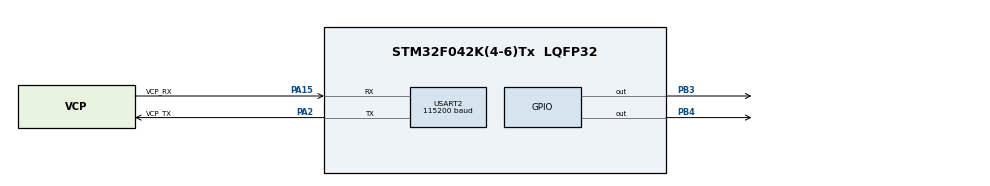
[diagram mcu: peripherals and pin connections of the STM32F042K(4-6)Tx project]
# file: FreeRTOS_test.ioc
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FREERTOS.Tasks01=defaultTask,0,128,StartDefaultTask,Default,NULL,Dynamic,NULL,NULL;Task2,0,128,Task2_init,Default,NULL,Dynamic,NULL,NULL
Mcu.Family=STM32F0
Mcu.Name=STM32F042K(4-6)Tx
Mcu.Package=LQFP32
NVIC.TIM17_IRQn=true\:3\:0\:false\:false\:true\:false\:false\:true
NVIC.TimeBase=TIM17_IRQn
NVIC.TimeBaseIP=TIM17
PA13.GPIO_Label=SWDIO
PA13.Mode=Serial_Wire
PA13.Signal=SYS_SWDIO
PA14.GPIO_Label=SWCLK
PA14.Mode=Serial_Wire
PA14.Signal=SYS_SWCLK
PA15.GPIO_Label=VCP_RX
PA15.Mode=Asynchronous
PA15.Signal=USART2_RX
PA2.GPIO_Label=VCP_TX
PA2.Mode=Asynchronous
PA2.Signal=USART2_TX
PB3.Signal=GPIO_Output
PB4.Signal=GPIO_Output
PF0-OSC_IN.GPIO_Label=MCO
PF0-OSC_IN.Mode=HSE-External-Clock-Source
PF0-OSC_IN.Signal=RCC_OSC_IN
ProjectManager.HeapSize=0x200
ProjectManager.StackSize=0x400
ProjectManager.TargetToolchain=MDK-ARM V5.32
USART2.BaudRate=115200
USART2.VirtualMode-Asynchronous=VM_ASYNC
VP_FREERTOS_VS_CMSIS_V1.Mode=CMSIS_V1
VP_SYS_VS_tim17.Mode=TIM17
board=NUCLEO-F042K6

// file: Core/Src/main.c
/* USER CODE BEGIN Header */
/**
  ******************************************************************************
  * @file           : main.c
  * @brief          : Main program body
  ******************************************************************************
  * @attention
  *
  * Copyright (c) 2022 STMicroelectronics.
  * All rights reserved.
  *
  * This software is licensed under terms that can be found in the LICENSE file
  * in the root directory of this software component.
  * If no LICENSE file comes with this software, it is provided AS-IS.
  *
  ******************************************************************************
  */
/* USER CODE END Header */
#include "main.h"
#include "cmsis_os.h"
#include "usart.h"
#include "gpio.h"

void SystemClock_Config(void);
void MX_FREERTOS_Init(void);

int main(void)
{

  /* MCU Configuration--------------------------------------------------------*/

  /* Reset of all peripherals, Initializes the Flash interface and the Systick. */
  HAL_Init();

  /* Configure the system clock */
  SystemClock_Config();

  /* Initialize all configured peripherals */
  MX_GPIO_Init();
  MX_USART2_UART_Init();

  /* Call init function for freertos objects (in freertos.c) */
  MX_FREERTOS_Init();
  /* Start scheduler */
  osKernelStart();

  /* We should never get here as control is now taken by the scheduler */
  /* Infinite loop */
  while (1)
  {

  }
}

void SystemClock_Config(void)
{
  RCC_OscInitTypeDef RCC_OscInitStruct = {0};
  RCC_ClkInitTypeDef RCC_ClkInitStruct = {0};

  /** Initializes the RCC Oscillators according to the specified parameters
  * in the RCC_OscInitTypeDef structure.
  */
  RCC_OscInitStruct.OscillatorType = RCC_OSCILLATORTYPE_HSI;
  RCC_OscInitStruct.HSIState = RCC_HSI_ON;
  RCC_OscInitStruct.HSICalibrationValue = RCC_HSICALIBRATION_DEFAULT;
  RCC_OscInitStruct.PLL.PLLState = RCC_PLL_NONE;
  if (HAL_RCC_OscConfig(&RCC_OscInitStruct) != HAL_OK)
  {
    Error_Handler();
  }
  /** Initializes the CPU, AHB and APB buses clocks
  */
  RCC_ClkInitStruct.ClockType = RCC_CLOCKTYPE_HCLK|RCC_CLOCKTYPE_SYSCLK
                              |RCC_CLOCKTYPE_PCLK1;
  RCC_ClkInitStruct.SYSCLKSource = RCC_SYSCLKSOURCE_HSI;
  RCC_ClkInitStruct.AHBCLKDivider = RCC_SYSCLK_DIV1;
  RCC_ClkInitStruct.APB1CLKDivider = RCC_HCLK_DIV1;

  if (HAL_RCC_ClockConfig(&RCC_ClkInitStruct, FLASH_LATENCY_0) != HAL_OK)
  {
    Error_Handler();
  }
}

void HAL_TIM_PeriodElapsedCallback(TIM_HandleTypeDef *htim)
{
  if (htim->Instance == TIM17) {
    HAL_IncTick();
  }
}

void Error_Handler(void)
{
  __disable_irq();
  while (1)
  {
  }
}

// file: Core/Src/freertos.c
/* USER CODE BEGIN Header */
/**
  ******************************************************************************
  * File Name          : freertos.c
  * Description        : Code for freertos applications
  ******************************************************************************
  * @attention
  *
  * Copyright (c) 2022 STMicroelectronics.
  * All rights reserved.
  *
  * This software is licensed under terms that can be found in the LICENSE file
  * in the root directory of this software component.
  * If no LICENSE file comes with this software, it is provided AS-IS.
  *
  ******************************************************************************
  */
/* USER CODE END Header */

#include "FreeRTOS.h"
#include "task.h"
#include "main.h"
#include "cmsis_os.h"

osThreadId defaultTaskHandle;
osThreadId Task2Handle;

void StartDefaultTask(void const * argument);
void Task2_init(void const * argument);

void MX_FREERTOS_Init(void); /* (MISRA C 2004 rule 8.1) */

/* GetIdleTaskMemory prototype (linked to static allocation support) */
void vApplicationGetIdleTaskMemory( StaticTask_t **ppxIdleTaskTCBBuffer, StackType_t **ppxIdleTaskStackBuffer, uint32_t *pulIdleTaskStackSize );

/* USER CODE BEGIN GET_IDLE_TASK_MEMORY */
static StaticTask_t xIdleTaskTCBBuffer;
static StackType_t xIdleStack[configMINIMAL_STACK_SIZE];

void vApplicationGetIdleTaskMemory( StaticTask_t **ppxIdleTaskTCBBuffer, StackType_t **ppxIdleTaskStackBuffer, uint32_t *pulIdleTaskStackSize )
{
  *ppxIdleTaskTCBBuffer = &xIdleTaskTCBBuffer;
  *ppxIdleTaskStackBuffer = &xIdleStack[0];
  *pulIdleTaskStackSize = configMINIMAL_STACK_SIZE;
  /* place for user code */
}
/* USER CODE END GET_IDLE_TASK_MEMORY */

void MX_FREERTOS_Init(void) {

  /* Create the thread(s) */
  /* definition and creation of defaultTask */
  osThreadDef(defaultTask, StartDefaultTask, osPriorityNormal, 0, 128);
  defaultTaskHandle = osThreadCreate(osThread(defaultTask), NULL);

  /* definition and creation of Task2 */
  osThreadDef(Task2, Task2_init, osPriorityNormal, 0, 128);
  Task2Handle = osThreadCreate(osThread(Task2), NULL);

}

void StartDefaultTask(void const * argument)
{
  /* USER CODE BEGIN StartDefaultTask */
  /* Infinite loop */
  for(;;)
  {
		HAL_GPIO_TogglePin(GPIOB, GPIO_PIN_3);
    osDelay(1000);
  }
  /* USER CODE END StartDefaultTask */
}

void Task2_init(void const * argument)
{
  /* USER CODE BEGIN Task2_init */
  /* Infinite loop */
  for(;;)
  {
		HAL_GPIO_TogglePin(GPIOB, GPIO_PIN_4);
    osDelay(1000);
  }
  /* USER CODE END Task2_init */
}
